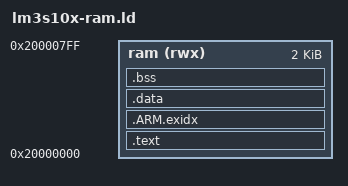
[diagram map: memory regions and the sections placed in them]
OUTPUT_FORMAT("elf32-littlearm", "elf32-bigarm",
	      "elf32-littlearm")
STARTUP(armv7m-crt0.o)
GROUP(-lc -lrdimon -lgcc)
OUTPUT_ARCH(arm)
ENTRY(_start)
SEARCH_DIR(.)
__DYNAMIC  =  0;

MEMORY
{
  
  ram (rwx) : ORIGIN = 0x20000000, LENGTH = 2k
}

/* Place the stack at the end of memory, unless specified otherwise. */
PROVIDE (__stack = 0x20000000 + 2k);

SECTIONS
{
  .text :
  {
    CREATE_OBJECT_SYMBOLS
    
    *(.text .text.* .gnu.linkonce.t.*)
    *(.plt)
    *(.gnu.warning)
    *(.glue_7t) *(.glue_7)

    . = ALIGN(0x4);
    /* These are for running static constructors and destructors under ELF.  */
    KEEP (*crtbegin.o(.ctors))
    KEEP (*(EXCLUDE_FILE (*crtend.o) .ctors))
    KEEP (*(SORT(.ctors.*)))
    KEEP (*crtend.o(.ctors))
    KEEP (*crtbegin.o(.dtors))
    KEEP (*(EXCLUDE_FILE (*crtend.o) .dtors))
    KEEP (*(SORT(.dtors.*)))
    KEEP (*crtend.o(.dtors))

    *(.rodata .rodata.* .gnu.linkonce.r.*)

    *(.ARM.extab* .gnu.linkonce.armextab.*)
    *(.gcc_except_table) 
    *(.eh_frame_hdr)
    *(.eh_frame)

    *(.init)
    *(.fini)

    PROVIDE_HIDDEN (__preinit_array_start = .);
    KEEP (*(.preinit_array))
    PROVIDE_HIDDEN (__preinit_array_end = .);
    PROVIDE_HIDDEN (__init_array_start = .);
    KEEP (*(SORT(.init_array.*)))
    KEEP (*(.init_array))
    PROVIDE_HIDDEN (__init_array_end = .);
    PROVIDE_HIDDEN (__fini_array_start = .);
    KEEP (*(.fini_array))
    KEEP (*(SORT(.fini_array.*)))
    PROVIDE_HIDDEN (__fini_array_end = .);
  } >ram
  /* .ARM.exidx is sorted, so has to go in its own output section.  */
   __exidx_start = .;
  .ARM.exidx :
  {
    *(.ARM.exidx* .gnu.linkonce.armexidx.*)
  } >ram
  __exidx_end = .;
  _etext = .;

  .data :
  {
    __data_load = LOADADDR (.data);
    __data_start = .;
    KEEP(*(.jcr))
    *(.got.plt) *(.got)
    *(.shdata)
    *(.data .data.* .gnu.linkonce.d.*)
    . = ALIGN (4);
    _edata = .;
  } >ram 

  .bss :
  {
    __bss_start__ = . ;
    *(.shbss)
    *(.bss .bss.* .gnu.linkonce.b.*)
    *(COMMON)
    . = ALIGN (8);
    __bss_end__ = .;
    _end = .;
    __end = _end;
    PROVIDE(end = .);
  } >ram 

  .stab 0 (NOLOAD) :
  {
    *(.stab)
  }

  .stabstr 0 (NOLOAD) :
  {
    *(.stabstr)
  }
  /* DWARF debug sections.
     Symbols in the DWARF debugging sections are relative to the beginning
     of the section so we begin them at 0.  */
  /* DWARF 1 */
  .debug          0 : { *(.debug) }
  .line           0 : { *(.line) }
  /* GNU DWARF 1 extensions */
  .debug_srcinfo  0 : { *(.debug_srcinfo) }
  .debug_sfnames  0 : { *(.debug_sfnames) }
  /* DWARF 1.1 and DWARF 2 */
  .debug_aranges  0 : { *(.debug_aranges) }
  .debug_pubnames 0 : { *(.debug_pubnames) }
  /* DWARF 2 */
  .debug_info     0 : { *(.debug_info .gnu.linkonce.wi.*) }
  .debug_abbrev   0 : { *(.debug_abbrev) }
  .debug_line     0 : { *(.debug_line) }
  .debug_frame    0 : { *(.debug_frame) }
  .debug_str      0 : { *(.debug_str) }
  .debug_loc      0 : { *(.debug_loc) }
  .debug_macinfo  0 : { *(.debug_macinfo) }
  /* SGI/MIPS DWARF 2 extensions */
  .debug_weaknames 0 : { *(.debug_weaknames) }
  .debug_funcnames 0 : { *(.debug_funcnames) }
  .debug_typenames 0 : { *(.debug_typenames) }
  .debug_varnames  0 : { *(.debug_varnames) }
  .note.gnu.arm.ident 0 : { KEEP (*(.note.gnu.arm.ident)) }
  .ARM.attributes 0 : { KEEP (*(.ARM.attributes)) }
  /DISCARD/ : { *(.note.GNU-stack) *(.isr_vector) }
}
